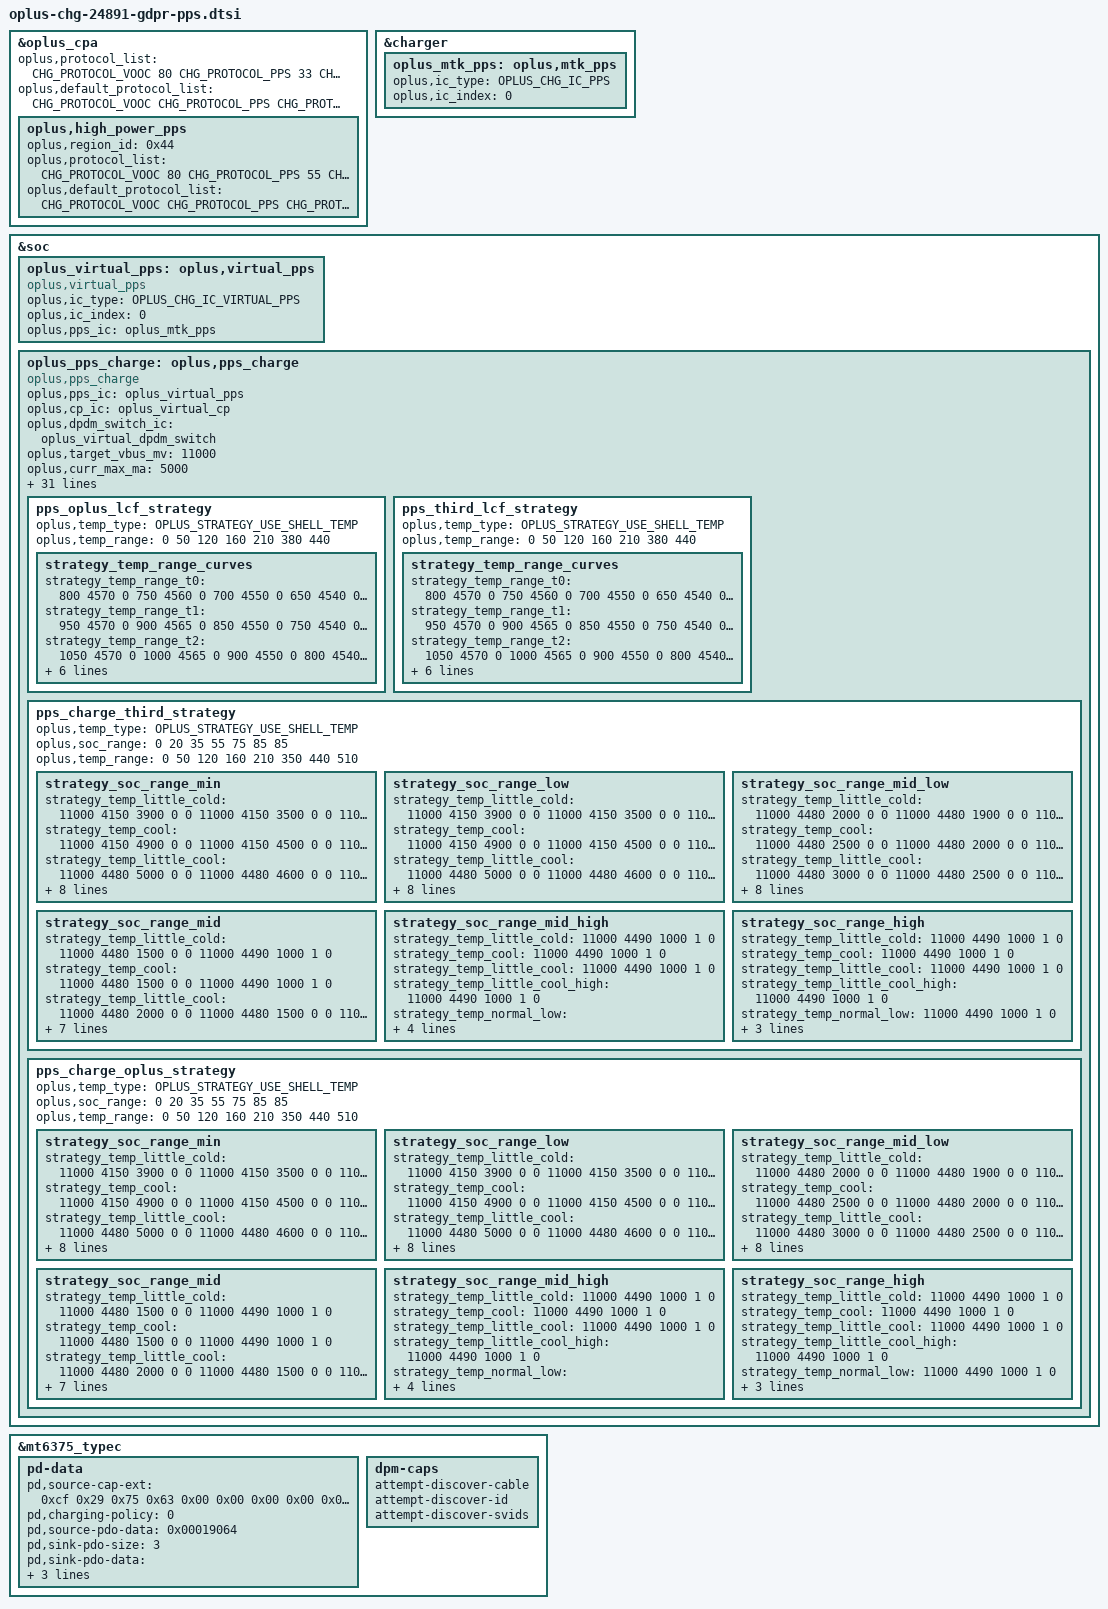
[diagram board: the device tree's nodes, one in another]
//ifdef OPLUS_FEATURE_CHG_BASIC
&oplus_cpa {
	oplus,protocol_list = <CHG_PROTOCOL_VOOC 80
			       CHG_PROTOCOL_PPS 33
			       CHG_PROTOCOL_PD 18
			       CHG_PROTOCOL_QC 18>;
	oplus,default_protocol_list = <CHG_PROTOCOL_VOOC
				       CHG_PROTOCOL_PPS
				       CHG_PROTOCOL_PD>;
	oplus,high_power_pps {
		oplus,region_id = /bits/ 8 <0x44>;
		oplus,protocol_list = <CHG_PROTOCOL_VOOC 80
				       CHG_PROTOCOL_PPS 55
				       CHG_PROTOCOL_PD 18
				       CHG_PROTOCOL_QC 18>;
		oplus,default_protocol_list = <CHG_PROTOCOL_VOOC
					       CHG_PROTOCOL_PPS
					       CHG_PROTOCOL_PD>;
	};
};

&charger {
	oplus_mtk_pps: oplus,mtk_pps {
		oplus,ic_type = <OPLUS_CHG_IC_PPS>;
		oplus,ic_index = <0>;
	};
};
&soc {
	oplus_virtual_pps: oplus,virtual_pps {
		compatible = "oplus,virtual_pps";

		oplus,ic_type = <OPLUS_CHG_IC_VIRTUAL_PPS>;
		oplus,ic_index = <0>;
		oplus,pps_ic = <&oplus_mtk_pps>;
	};
	oplus_pps_charge: oplus,pps_charge {
		compatible = "oplus,pps_charge";
		oplus,pps_ic = <&oplus_virtual_pps>;
		oplus,cp_ic = <&oplus_virtual_cp>;
		oplus,dpdm_switch_ic = <&oplus_virtual_dpdm_switch>;

		oplus,target_vbus_mv = <11000>;
		oplus,curr_max_ma = <5000>;

		oplus,curr_max_ma_percent = <2000 /* 75% ibus */
					     1000 /* 85% ibus */>;

		oplus,pps_warm_allow_vol = <4000>;
		oplus,pps_warm_allow_soc = <50>;
		oplus,pps_strategy_normal_current = <5000>;
		oplus,pps_over_high_or_low_current = <3000>;
		oplus,pps_timeout_third = <17820>;
		oplus,pps_timeout_oplus = <17820>;
		oplus,pps_ibat_over_third = <11400>;
		oplus,pps_ibat_over_oplus = <11400>;
		oplus,pps_full_cool_sw_vbat = <4490>;
		oplus,pps_full_normal_sw_vbat = <4490>;
		oplus,pps_full_normal_hw_vbat = <4500>;
		oplus,pps_full_ffc_vbat = <4500>;
		oplus,pps_full_warm_vbat = <4130>;
		oplus,pps_full_cool_sw_vbat_third = <4490>;
		oplus,pps_full_normal_sw_vbat_third= <4490>;
		oplus,pps_full_normal_hw_vbat_third = <4500>;
		oplus,pps_current_change_timeout = <100>;
		oplus,curve_strategy_name = "pps_ufcs_curve_v2";
		oplus,pps_strategy_batt_high_temp = <410 420 430 400 410 420>;
		oplus,pps_strategy_high_current = <5000 4000 3000 5000 4000 3000>;
		oplus,pps_little_cool_high_temp = <210>;
		oplus,pps_charge_strategy_soc = <0 20 35 55 75 85 85>;
		oplus,pps_charge_strategy_temp = <0 50 120 160 350 440 510>;

		oplus,plc_strategy-data = <&cp_2t1_simple_strategy>;
		oplus,plc_strategy-names = "default";

		pps_oplus_lcf_strategy {
			oplus,temp_type = <OPLUS_STRATEGY_USE_SHELL_TEMP>;
			oplus,temp_range = <0 50 120 160 210 380 440>;

			strategy_temp_range_curves {
				strategy_temp_range_t0 =	<800 4570 0
								 750 4560 0
								 700 4550 0
								 650 4540 0
								 600 4530 1>;
				strategy_temp_range_t1 =	<950 4570 0
								 900 4565 0
								 850 4550 0
								 750 4540 0
								 650 4530 1>;
				strategy_temp_range_t2 =	<1050 4570 0
								 1000 4565 0
								 900 4550 0
								 800 4540 0
								 650 4530 1>;
				strategy_temp_range_t3 =	<1600 4570 0
								 1550 4565 0
								 1450 4550 0
								 1350 4540 0
								 1200 4530 1>;
				strategy_temp_range_t4 =	<2150 4549 0
								 1950 4540 0
								 1650 4529 0
								 1350 4515 0
								 1000 4495 1>;
				strategy_temp_range_t5 =	<2850 4558 0
								 2650 4535 0
								 2100 4512 0
								 1550 4495 0
								 1000 4480 1>;
			};
		};

		pps_third_lcf_strategy {
			oplus,temp_type = <OPLUS_STRATEGY_USE_SHELL_TEMP>;
			oplus,temp_range = <0 50 120 160 210 380 440>;

			strategy_temp_range_curves {
				strategy_temp_range_t0 =	<800 4570 0
								 750 4560 0
								 700 4550 0
								 650 4540 0
								 600 4530 1>;
				strategy_temp_range_t1 =	<950 4570 0
								 900 4565 0
								 850 4550 0
								 750 4540 0
								 650 4530 1>;
				strategy_temp_range_t2 =	<1050 4570 0
								 1000 4565 0
								 900 4550 0
								 800 4540 0
								 650 4530 1>;
				strategy_temp_range_t3 =	<1600 4570 0
								 1550 4565 0
								 1450 4550 0
								 1350 4540 0
								 1200 4530 1>;
				strategy_temp_range_t4 =	<2150 4549 0
								 1950 4540 0
								 1650 4529 0
								 1350 4515 0
								 1000 4495 1>;
				strategy_temp_range_t5 =	<2850 4558 0
								 2650 4535 0
								 2100 4512 0
								 1550 4495 0
								 1000 4480 1>;
			};
		};

		pps_charge_third_strategy {
			oplus,temp_type = <OPLUS_STRATEGY_USE_SHELL_TEMP>;
			oplus,soc_range = <0 20 35 55 75 85 85>;
			oplus,temp_range = <0 50 120 160 210 350 440 510>;

			strategy_soc_range_min {
				strategy_temp_little_cold =	<11000 4150 3900 0 0
								11000 4150 3500 0 0
								11000 4150 3000 0 0
								11000 4480 2600 0 0
								11000 4480 2500 0 0
								11000 4480 2000 0 0
								11000 4480 1900 0 0
								11000 4480 1500 0 0
								11000 4490 1000 1 0>;
				strategy_temp_cool =		<11000 4150 4900 0 0
								11000 4150 4500 0 0
								11000 4150 4000 0 0
								11000 4480 3900 0 0
								11000 4480 3500 0 0
								11000 4480 3000 0 0
								11000 4480 2600 0 0
								11000 4480 2500 0 0
								11000 4480 2000 0 0
								11000 4480 1500 0 0
								11000 4490 1000 1 0>;
				strategy_temp_little_cool =	<11000 4480 5000 0 0
								11000 4480 4600 0 0
								11000 4480 4500 0 0
								11000 4480 4000 0 0
								11000 4480 3000 0 0
								11000 4480 2500 0 0
								11000 4480 2000 0 0
								11000 4480 1500 0 0
								11000 4490 1000 1 0>;
				strategy_temp_little_cool_high =	<11000 4480 5000 0 0
								11000 4480 4600 0 0
								11000 4480 4500 0 0
								11000 4480 4000 0 0
								11000 4480 3000 0 0
								11000 4480 2500 0 0
								11000 4480 2000 0 0
								11000 4480 1500 0 0
								11000 4490 1000 1 0>;
				strategy_temp_normal_low =	<11000 4480 5000 0 0
								11000 4480 4600 0 0
								11000 4480 4500 0 0
								11000 4480 4000 0 0
								11000 4480 3000 0 0
								11000 4480 2500 0 0
								11000 4480 2000 0 0
								11000 4480 1500 0 0
								11000 4490 1000 1 0>;
				strategy_temp_normal_high =	<11000 4460 5000 0 0
								11000 4460 4600 0 0
								11000 4460 4500 0 0
								11000 4460 4000 0 0
								11000 4460 3000 0 0
								11000 4460 2500 0 0
								11000 4460 2000 0 0
								11000 4460 1500 0 0
								11000 4470 1000 1 0>;
				strategy_temp_warm =		<11000 4120 1900 0 0
								11000 4120 1500 0 0
								11000 4130 1000 1 0>;
			};
			strategy_soc_range_low {
				strategy_temp_little_cold =	<11000 4150 3900 0 0
								11000 4150 3500 0 0
								11000 4150 3000 0 0
								11000 4480 2600 0 0
								11000 4480 2500 0 0
								11000 4480 2000 0 0
								11000 4480 1900 0 0
								11000 4480 1500 0 0
								11000 4490 1000 1 0>;
				strategy_temp_cool =		<11000 4150 4900 0 0
								11000 4150 4500 0 0
								11000 4150 4000 0 0
								11000 4480 3900 0 0
								11000 4480 3500 0 0
								11000 4480 3000 0 0
								11000 4480 2600 0 0
								11000 4480 2500 0 0
								11000 4480 2000 0 0
								11000 4480 1500 0 0
								11000 4490 1000 1 0>;
				strategy_temp_little_cool =	<11000 4480 5000 0 0
								11000 4480 4600 0 0
								11000 4480 4500 0 0
								11000 4480 4000 0 0
								11000 4480 3000 0 0
								11000 4480 2500 0 0
								11000 4480 2000 0 0
								11000 4480 1500 0 0
								11000 4490 1000 1 0>;
				strategy_temp_little_cool_high =	<11000 4480 5000 0 0
								11000 4480 4600 0 0
								11000 4480 4500 0 0
								11000 4480 4000 0 0
								11000 4480 3000 0 0
								11000 4480 2500 0 0
								11000 4480 2000 0 0
								11000 4480 1500 0 0
								11000 4490 1000 1 0>;
				strategy_temp_normal_low =	<11000 4480 5000 0 0
								11000 4480 4600 0 0
								11000 4480 4500 0 0
								11000 4480 4000 0 0
								11000 4480 3000 0 0
								11000 4480 2500 0 0
								11000 4480 2000 0 0
								11000 4480 1500 0 0
								11000 4490 1000 1 0>;
				strategy_temp_normal_high =	<11000 4460 5000 0 0
								11000 4460 4600 0 0
								11000 4460 4500 0 0
								11000 4460 4000 0 0
								11000 4460 3000 0 0
								11000 4460 2500 0 0
								11000 4460 2000 0 0
								11000 4460 1500 0 0
								11000 4470 1000 1 0>;
				strategy_temp_warm =		<11000 4120 1900 0 0
								11000 4120 1500 0 0
								11000 4130 1000 1 0>;
			};
			strategy_soc_range_mid_low {
				strategy_temp_little_cold =	<11000 4480 2000 0 0
								11000 4480 1900 0 0
								11000 4480 1500 0 0
								11000 4490 1000 1 0>;
				strategy_temp_cool =		<11000 4480 2500 0 0
								11000 4480 2000 0 0
								11000 4480 1500 0 0
								11000 4490 1000 1 0>;
				strategy_temp_little_cool =	<11000 4480 3000 0 0
								11000 4480 2500 0 0
								11000 4480 2000 0 0
								11000 4480 1500 0 0
								11000 4490 1000 1 0>;
				strategy_temp_little_cool_high =	<11000 4480 3000 0 0
								11000 4480 2500 0 0
								11000 4480 2000 0 0
								11000 4480 1500 0 0
								11000 4490 1000 1 0>;
				strategy_temp_normal_low =	<11000 4480 5000 0 0
								11000 4480 4600 0 0
								11000 4480 4500 0 0
								11000 4480 4000 0 0
								11000 4480 3000 0 0
								11000 4480 2500 0 0
								11000 4480 2000 0 0
								11000 4480 1500 0 0
								11000 4490 1000 1 0>;
				strategy_temp_normal_high =	<11000 4460 5000 0 0
								11000 4460 4600 0 0
								11000 4460 4500 0 0
								11000 4460 4000 0 0
								11000 4460 3000 0 0
								11000 4460 2500 0 0
								11000 4460 2000 0 0
								11000 4460 1500 0 0
								11000 4470 1000 1 0>;
				strategy_temp_warm =		<11000 4120 1900 0 0
								11000 4120 1500 0 0
								11000 4130 1000 1 0>;
			};
			strategy_soc_range_mid {
				strategy_temp_little_cold =	<11000 4480 1500 0 0
								11000 4490 1000 1 0>;
				strategy_temp_cool =		<11000 4480 1500 0 0
								11000 4490 1000 1 0>;
				strategy_temp_little_cool =	<11000 4480 2000 0 0
								11000 4480 1500 0 0
								11000 4490 1000 1 0>;
				strategy_temp_little_cool_high =	<11000 4480 2000 0 0
								11000 4480 1500 0 0
								11000 4490 1000 1 0>;
				strategy_temp_normal_low =	<11000 4480 2000 0 0
								11000 4480 1500 0 0
								11000 4490 1000 1 0>;
				strategy_temp_normal_high =	<11000 4460 2500 0 0
								11000 4460 2000 0 0
								11000 4460 1500 0 0
								11000 4470 1000 1 0>;
				strategy_temp_warm =		<11000 4130 1000 1 0>;
			};
			strategy_soc_range_mid_high {
				strategy_temp_little_cold =	<11000 4490 1000 1 0>;
				strategy_temp_cool =		<11000 4490 1000 1 0>;
				strategy_temp_little_cool =	<11000 4490 1000 1 0>;
				strategy_temp_little_cool_high =	<11000 4490 1000 1 0>;
				strategy_temp_normal_low =	<11000 4480 1500 0 0
								11000 4490 1000 1 0>;
				strategy_temp_normal_high =	<11000 4460 1500 0 0
								11000 4470 1000 1 0>;
				strategy_temp_warm =		<11000 4130 1000 1 0>;
			};
			strategy_soc_range_high {
				strategy_temp_little_cold =	<11000 4490 1000 1 0>;
				strategy_temp_cool =		<11000 4490 1000 1 0>;
				strategy_temp_little_cool =	<11000 4490 1000 1 0>;
				strategy_temp_little_cool_high =	<11000 4490 1000 1 0>;
				strategy_temp_normal_low =	<11000 4490 1000 1 0>;
				strategy_temp_normal_high =	<11000 4460 1500 0 0
								11000 4470 1000 1 0>;
				strategy_temp_warm =		<11000 4130 1000 1 0>;
			};
		};


		pps_charge_oplus_strategy {
			oplus,temp_type = <OPLUS_STRATEGY_USE_SHELL_TEMP>;
			oplus,soc_range = <0 20 35 55 75 85 85>;
			oplus,temp_range = <0 50 120 160 210 350 440 510>;

			strategy_soc_range_min {
				strategy_temp_little_cold =	<11000 4150 3900 0 0
								11000 4150 3500 0 0
								11000 4150 3000 0 0
								11000 4480 2600 0 0
								11000 4480 2500 0 0
								11000 4480 2000 0 0
								11000 4480 1900 0 0
								11000 4480 1500 0 0
								11000 4490 1000 1 0>;
				strategy_temp_cool =		<11000 4150 4900 0 0
								11000 4150 4500 0 0
								11000 4150 4000 0 0
								11000 4480 3900 0 0
								11000 4480 3500 0 0
								11000 4480 3000 0 0
								11000 4480 2600 0 0
								11000 4480 2500 0 0
								11000 4480 2000 0 0
								11000 4480 1500 0 0
								11000 4490 1000 1 0>;
				strategy_temp_little_cool =	<11000 4480 5000 0 0
								11000 4480 4600 0 0
								11000 4480 4500 0 0
								11000 4480 4000 0 0
								11000 4480 3000 0 0
								11000 4480 2500 0 0
								11000 4480 2000 0 0
								11000 4480 1500 0 0
								11000 4490 1000 1 0>;
				strategy_temp_little_cool_high =	<11000 4480 5000 0 0
								11000 4480 4600 0 0
								11000 4480 4500 0 0
								11000 4480 4000 0 0
								11000 4480 3000 0 0
								11000 4480 2500 0 0
								11000 4480 2000 0 0
								11000 4480 1500 0 0
								11000 4490 1000 1 0>;
				strategy_temp_normal_low =	<11000 4480 5000 0 0
								11000 4480 4600 0 0
								11000 4480 4500 0 0
								11000 4480 4000 0 0
								11000 4480 3000 0 0
								11000 4480 2500 0 0
								11000 4480 2000 0 0
								11000 4480 1500 0 0
								11000 4490 1000 1 0>;
				strategy_temp_normal_high =	<11000 4460 5000 0 0
								11000 4460 4600 0 0
								11000 4460 4500 0 0
								11000 4460 4000 0 0
								11000 4460 3000 0 0
								11000 4460 2500 0 0
								11000 4460 2000 0 0
								11000 4460 1500 0 0
								11000 4470 1000 1 0>;
				strategy_temp_warm =		<11000 4120 1900 0 0
								11000 4120 1500 0 0
								11000 4130 1000 1 0>;
			};
			strategy_soc_range_low {
				strategy_temp_little_cold =	<11000 4150 3900 0 0
								11000 4150 3500 0 0
								11000 4150 3000 0 0
								11000 4480 2600 0 0
								11000 4480 2500 0 0
								11000 4480 2000 0 0
								11000 4480 1900 0 0
								11000 4480 1500 0 0
								11000 4490 1000 1 0>;
				strategy_temp_cool =		<11000 4150 4900 0 0
								11000 4150 4500 0 0
								11000 4150 4000 0 0
								11000 4480 3900 0 0
								11000 4480 3500 0 0
								11000 4480 3000 0 0
								11000 4480 2600 0 0
								11000 4480 2500 0 0
								11000 4480 2000 0 0
								11000 4480 1500 0 0
								11000 4490 1000 1 0>;
				strategy_temp_little_cool =	<11000 4480 5000 0 0
								11000 4480 4600 0 0
								11000 4480 4500 0 0
								11000 4480 4000 0 0
								11000 4480 3000 0 0
								11000 4480 2500 0 0
								11000 4480 2000 0 0
								11000 4480 1500 0 0
								11000 4490 1000 1 0>;
				strategy_temp_little_cool_high =	<11000 4480 5000 0 0
								11000 4480 4600 0 0
								11000 4480 4500 0 0
								11000 4480 4000 0 0
								11000 4480 3000 0 0
								11000 4480 2500 0 0
								11000 4480 2000 0 0
								11000 4480 1500 0 0
								11000 4490 1000 1 0>;
				strategy_temp_normal_low =	<11000 4480 5000 0 0
								11000 4480 4600 0 0
								11000 4480 4500 0 0
								11000 4480 4000 0 0
								11000 4480 3000 0 0
								11000 4480 2500 0 0
								11000 4480 2000 0 0
								11000 4480 1500 0 0
								11000 4490 1000 1 0>;
				strategy_temp_normal_high =	<11000 4460 5000 0 0
								11000 4460 4600 0 0
								11000 4460 4500 0 0
								11000 4460 4000 0 0
								11000 4460 3000 0 0
								11000 4460 2500 0 0
								11000 4460 2000 0 0
								11000 4460 1500 0 0
								11000 4470 1000 1 0>;
				strategy_temp_warm =		<11000 4120 1900 0 0
								11000 4120 1500 0 0
								11000 4130 1000 1 0>;
			};
			strategy_soc_range_mid_low {
				strategy_temp_little_cold =	<11000 4480 2000 0 0
								11000 4480 1900 0 0
								11000 4480 1500 0 0
								11000 4490 1000 1 0>;
				strategy_temp_cool =		<11000 4480 2500 0 0
								11000 4480 2000 0 0
								11000 4480 1500 0 0
								11000 4490 1000 1 0>;
				strategy_temp_little_cool =	<11000 4480 3000 0 0
								11000 4480 2500 0 0
								11000 4480 2000 0 0
								11000 4480 1500 0 0
								11000 4490 1000 1 0>;
				strategy_temp_little_cool_high =	<11000 4480 3000 0 0
								11000 4480 2500 0 0
								11000 4480 2000 0 0
								11000 4480 1500 0 0
								11000 4490 1000 1 0>;
				strategy_temp_normal_low =	<11000 4480 5000 0 0
								11000 4480 4600 0 0
								11000 4480 4500 0 0
								11000 4480 4000 0 0
								11000 4480 3000 0 0
								11000 4480 2500 0 0
								11000 4480 2000 0 0
								11000 4480 1500 0 0
								11000 4490 1000 1 0>;
				strategy_temp_normal_high =	<11000 4460 5000 0 0
								11000 4460 4600 0 0
								11000 4460 4500 0 0
								11000 4460 4000 0 0
								11000 4460 3000 0 0
								11000 4460 2500 0 0
								11000 4460 2000 0 0
								11000 4460 1500 0 0
								11000 4470 1000 1 0>;
				strategy_temp_warm =		<11000 4120 1900 0 0
								11000 4120 1500 0 0
								11000 4130 1000 1 0>;
			};
			strategy_soc_range_mid {
				strategy_temp_little_cold =	<11000 4480 1500 0 0
								11000 4490 1000 1 0>;
				strategy_temp_cool =		<11000 4480 1500 0 0
								11000 4490 1000 1 0>;
				strategy_temp_little_cool =	<11000 4480 2000 0 0
								11000 4480 1500 0 0
								11000 4490 1000 1 0>;
				strategy_temp_little_cool_high =	<11000 4480 2000 0 0
								11000 4480 1500 0 0
								11000 4490 1000 1 0>;
				strategy_temp_normal_low =	<11000 4480 2000 0 0
								11000 4480 1500 0 0
								11000 4490 1000 1 0>;
				strategy_temp_normal_high =	<11000 4460 2500 0 0
								11000 4460 2000 0 0
								11000 4460 1500 0 0
								11000 4470 1000 1 0>;
				strategy_temp_warm =		<11000 4130 1000 1 0>;
			};
			strategy_soc_range_mid_high {
				strategy_temp_little_cold =	<11000 4490 1000 1 0>;
				strategy_temp_cool =		<11000 4490 1000 1 0>;
				strategy_temp_little_cool =	<11000 4490 1000 1 0>;
				strategy_temp_little_cool_high =	<11000 4490 1000 1 0>;
				strategy_temp_normal_low =	<11000 4480 1500 0 0
								11000 4490 1000 1 0>;
				strategy_temp_normal_high =	<11000 4460 1500 0 0
								11000 4470 1000 1 0>;
				strategy_temp_warm =		<11000 4130 1000 1 0>;
			};
			strategy_soc_range_high {
				strategy_temp_little_cold =	<11000 4490 1000 1 0>;
				strategy_temp_cool =		<11000 4490 1000 1 0>;
				strategy_temp_little_cool =	<11000 4490 1000 1 0>;
				strategy_temp_little_cool_high =	<11000 4490 1000 1 0>;
				strategy_temp_normal_low =	<11000 4490 1000 1 0>;
				strategy_temp_normal_high =	<11000 4460 1500 0 0
								11000 4470 1000 1 0>;
				strategy_temp_warm =		<11000 4130 1000 1 0>;
			};
		};
	};
};

/* for pd common charger */
&mt6375_typec {
	pd-data {
			pd,source-cap-ext = /bits/ 8 <0xcf 0x29 0x75 0x63
							      0x00 0x00 0x00 0x00
							      0x00 0x00 0x00 0x00
							      0x00 0x00 0x00 0x00
							      0x00 0x00 0x00 0x00
							      0x00 0x00 0x01 0x05
							      0x00>;

			pd,charging-policy = <0>;

			pd,source-pdo-data = <0x00019064>;/* Fixed, 5000mV, 1000mA*/

			/*0x000190c8: Fixed, 5000mV, 2000mA*/
			/*0x0002d096: Fixed, 9000mV, 1500mA*/
			/*0xc0dc1e64: apdo, min 3000mV, max 11000mV, 5000mA*/
			pd,sink-pdo-size = <3>;
			pd,sink-pdo-data = <0x000190c8 0x0002d096 0xc0dc1e64>;

			/* No DP, host + device */
			pd,id-vdo-data = <0xd14029cf 0x0 0x63750000
						  0x61000000 0x0 0x41000000>;
	};

	dpm-caps {
			// attempt-enter-dp-mode;
			attempt-discover-cable;
			attempt-discover-id;
			attempt-discover-svids;
	};
};

//#endif OPLUS_FEATURE_CHG_BASIC
